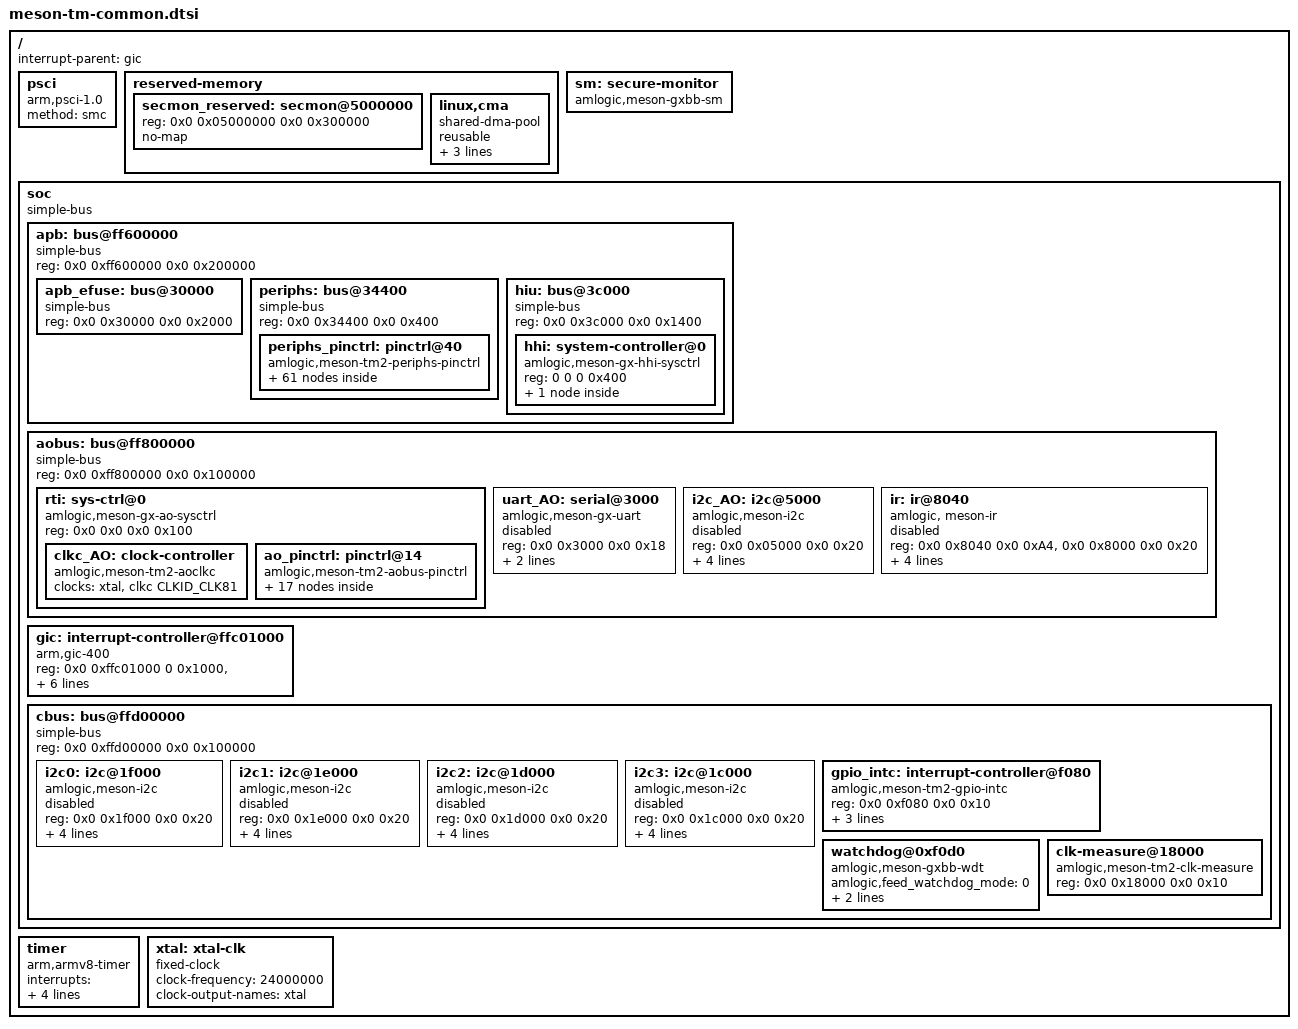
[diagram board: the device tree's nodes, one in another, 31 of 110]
// SPDX-License-Identifier: (GPL-2.0+ OR MIT)
/*
 * Copyright (c) 2018 Amlogic, Inc. All rights reserved.
 */

#include <dt-bindings/clock/tm2-clkc.h>
#include <dt-bindings/clock/tm2-aoclkc.h>
#include <dt-bindings/interrupt-controller/irq.h>
#include <dt-bindings/interrupt-controller/arm-gic.h>
#include <dt-bindings/gpio/gpio.h>
#include <dt-bindings/gpio/meson-tm2-gpio.h>
#include <dt-bindings/input/input.h>
#include <dt-bindings/input/meson_ir.h>
#include "meson-ir-map.dtsi"

/ {
	interrupt-parent = <&gic>;
	#address-cells = <2>;
	#size-cells = <2>;

	psci {
		compatible = "arm,psci-1.0";
		method = "smc";
	};

	reserved-memory {
		#address-cells = <2>;
		#size-cells = <2>;
		ranges;

		/* 3 MiB reserved for ARM Trusted Firmware (BL31) */
		secmon_reserved: secmon@5000000 {
			reg = <0x0 0x05000000 0x0 0x300000>;
			no-map;
		};
		linux,cma {
			compatible = "shared-dma-pool";
			reusable;
			size = <0x0 0x10000000>;
			alignment = <0x0 0x400000>;
			linux,cma-default;
		};
	};

	sm: secure-monitor {
		compatible = "amlogic,meson-gxbb-sm";
	};

	soc {
		compatible = "simple-bus";
		#address-cells = <2>;
		#size-cells = <2>;
		ranges;

		apb: bus@ff600000 {
			compatible = "simple-bus";
			reg = <0x0 0xff600000 0x0 0x200000>;
			#address-cells = <2>;
			#size-cells = <2>;
			ranges = <0x0 0x0 0x0 0xff600000 0x0 0x200000>;

			apb_efuse: bus@30000 {
				compatible = "simple-bus";
				reg = <0x0 0x30000 0x0 0x2000>;
				#address-cells = <2>;
				#size-cells = <2>;
				ranges = <0x0 0x0 0x0 0x30000 0x0 0x2000>;
			};

			periphs: bus@34400 {
				compatible = "simple-bus";
				reg = <0x0 0x34400 0x0 0x400>;
				#address-cells = <2>;
				#size-cells = <2>;
				ranges = <0x0 0x0 0x0 0x34400 0x0 0x400>;

				periphs_pinctrl: pinctrl@40 {
					compatible =
					"amlogic,meson-tm2-periphs-pinctrl";
					#address-cells = <2>;
					#size-cells = <2>;
					ranges;

					gpio: bank@40 {
						reg = <0x0 0x40  0x0 0x4c>,
						      <0x0 0xe8  0x0 0x18>,
						      <0x0 0x120 0x0 0x18>,
						      <0x0 0x2c0 0x0 0x40>,
						      <0x0 0x340 0x0 0x1c>;
						reg-names = "gpio",
							    "pull",
							    "pull-enable",
							    "mux",
							    "ds";
						gpio-controller;
						#gpio-cells = <2>;
						gpio-ranges = <&periphs_pinctrl
							      0 0 89>;
					};

					i2c0_c_pins:i2c0_c {
						mux {
							groups = "i2c0_sda_c",
								"i2c0_sck_c";
							function = "i2c0";
							bias-disable;
							drive-strength-microamp = <3000>;
						};
					};

					i2c0_c_pins_slp_input:i2c0_c_slp_input {
						mux {
							groups = "GPIOC_8", "GPIOC_9";
							function = "gpio_periphs";
							input-enable;
							bias-disable;
						};
					};

					i2c0_c_pins_slp_low:i2c0_c_slp_low {
						mux {
							groups = "GPIOC_8", "GPIOC_9";
							function = "gpio_periphs";
							output-low;
						};
					};

					i2c0_dv_pins:i2c0_dv {
						mux {
							groups = "i2c0_sda_dv",
								"i2c0_sck_dv";
							function = "i2c0";
							bias-disable;
							drive-strength-microamp = <3000>;
						};
					};

					i2c0_dv_pins_slp_input:i2c0_dv_slp_input {
						mux {
							groups = "GPIODV_0", "GPIODV_1";
							function = "gpio_periphs";
							input-enable;
							bias-disable;
						};
					};

					i2c0_dv_pins_slp_low:i2c0_dv_slp_low {
						mux {
							groups = "GPIODV_0", "GPIODV_1";
							function = "gpio_periphs";
							output-low;
						};
					};

					i2c1_z_pins:i2c1_z {
						mux {
							groups = "i2c1_sda_z",
								"i2c1_sck_z";
							function = "i2c1";
							bias-disable;
							drive-strength-microamp = <3000>;
						};
					};

					/*
					 * i2c sleep mode1: set the gpio the input
					 * in this scene, pull up power is off
					 */
					i2c1_z_pins_slp_input:i2c1_z_slp_input {
						mux {
							groups = "GPIOZ_1", "GPIOZ_2";
							function = "gpio_periphs";
							input-enable;
							bias-disable;
						};
					};

					/*
					 * i2c sleep mode2: set the gpio low
					 * in this scene, pull up power is on
					 */
					i2c1_z_pins_slp_low:i2c1_z_slp_low {
						mux {
							groups = "GPIOZ_1", "GPIOZ_2";
							function = "gpio_periphs";
							output-low;
						};
					};

					i2c1_h_pins:i2c1_h {
						mux {
							groups = "i2c1_sda_h",
								"i2c1_sck_h";
							function = "i2c1";
							bias-disable;
							drive-strength-microamp = <3000>;
						};
					};

					i2c1_h_pins_slp_input:i2c1_h_slp_input {
						mux {
							groups = "GPIOH_21", "GPIOH_22";
							function = "gpio_periphs";
							input-enable;
							bias-disable;
						};
					};

					i2c1_h_pins_slp_low:i2c1_h_slp_low {
						mux {
							groups = "GPIOH_21", "GPIOH_22";
							function = "gpio_periphs";
							output-low;
						};
					};

					i2c2_h_pins:i2c2_h {
						mux {
							groups = "i2c2_sda_h",
								"i2c2_sck_h";
							function = "i2c2";
							bias-disable;
							drive-strength-microamp = <3000>;
						};
					};

					i2c2_h_pins_slp_input:i2c2_h_slp_input {
						mux {
							groups = "GPIOH_19", "GPIOH_20";
							function = "gpio_periphs";
							input-enable;
							bias-disable;
						};
					};

					i2c2_h_pins_slp_low:i2c2_h_slp_low {
						mux {
							groups = "GPIOH_19", "GPIOH_20";
							function = "gpio_periphs";
							output-low;
						};
					};

					i2c2_z_pins:i2c2_z {
						mux {
							groups = "i2c2_sda_z",
								"i2c2_sck_z";
							function = "i2c2";
							bias-disable;
							drive-strength-microamp = <3000>;
						};
					};

					i2c2_z_pins_slp_input:i2c2_z_slp_input {
						mux {
							groups = "GPIOZ_9", "GPIOZ_10";
							function = "gpio_periphs";
							input-enable;
							bias-disable;
						};
					};

					i2c2_z_pins_slp_low:i2c2_z_slp_low {
						mux {
							groups = "GPIOZ_9", "GPIOZ_10";
							function = "gpio_periphs";
							output-low;
						};
					};

					i2c3_h1_pins:i2c3_h1 {
						mux {
							groups = "i2c3_sda_h1",
								"i2c3_sck_h0";
							function = "i2c3";
							bias-disable;
							drive-strength-microamp = <3000>;
						};
					};

					i2c3_h1_pins_slp_input:i2c3_h1_slp_input {
						mux {
							groups = "GPIOH_0", "GPIOH_1";
							function = "gpio_periphs";
							input-enable;
							bias-disable;
						};
					};

					i2c3_h1_pins_slp_low:i2c3_h1_slp_low {
						mux {
							groups = "GPIOH_0", "GPIOH_1";
							function = "gpio_periphs";
							output-low;
						};
					};

					i2c3_h20_pins:i2c3_h3 {
						mux {
							groups = "i2c3_sda_h20",
								"i2c3_sck_h19";
							function = "i2c3";
							bias-disable;
							drive-strength-microamp = <3000>;
						};
					};

					i2c3_h20_pins_slp_input:i2c3_h20_slp_input {
						mux {
							groups = "GPIOH_19", "GPIOH_20";
							function = "gpio_periphs";
							input-enable;
							bias-disable;
						};
					};

					i2c3_h20_pins_slp_low:i2c3_h20_slp_low {
						mux {
							groups = "GPIOH_19", "GPIOH_20";
							function = "gpio_periphs";
							output-low;
						};
					};

					i2c3_dv_pins:i2c3_dv {
						mux {
							groups = "i2c3_sda_dv",
								"i2c3_sck_dv";
							function = "i2c3";
							bias-disable;
							drive-strength-microamp = <3000>;
						};
					};

					i2c3_dv_pins_slp_input:i2c3_dv_slp_input {
						mux {
							groups = "GPIODV_9", "GPIODV_10";
							function = "gpio_periphs";
							input-enable;
							bias-disable;
						};
					};

					i2c3_dv_pins_slp_low:i2c3_dv_slp_low {
						mux {
							groups = "GPIODV_9", "GPIODV_10";
							function = "gpio_periphs";
							output-low;
						};
					};

					i2c3_c_pins:i2c3_c {
						mux {
							groups = "i2c3_sda_c",
								"i2c3_sck_c";
							function = "i2c3";
							bias-disable;
							drive-strength-microamp = <3000>;
						};
					};

					i2c3_c_pins_slp_input:i2c3_c_slp_input {
						mux {
							groups = "GPIOC_13", "GPIOC_14";
							function = "gpio_periphs";
							input-enable;
							bias-disable;
						};
					};

					i2c3_c_pins_slp_low:i2c3_c_slp_low {
						mux {
							groups = "GPIOC_13", "GPIOC_14";
							function = "gpio_periphs";
							output-low;
						};
					};
				};
			};

			hiu: bus@3c000 {
				compatible = "simple-bus";
				reg = <0x0 0x3c000 0x0 0x1400>;
				#address-cells = <2>;
				#size-cells = <2>;
				ranges = <0x0 0x0 0x0 0x3c000 0x0 0x1400>;

				hhi: system-controller@0 {
					compatible = "amlogic,meson-gx-hhi-sysctrl",
						     "simple-mfd", "syscon";
					reg = <0 0 0 0x400>;

					clkc: clock-controller {
						compatible = "amlogic,tm2-clkc";
						#clock-cells = <1>;
						clocks = <&xtal>;
						clock-names = "xtal";
					};
				};
			};
		};

		aobus: bus@ff800000 {
			compatible = "simple-bus";
			reg = <0x0 0xff800000 0x0 0x100000>;
			#address-cells = <2>;
			#size-cells = <2>;
			ranges = <0x0 0x0 0x0 0xff800000 0x0 0x100000>;

		rti: sys-ctrl@0 {
			compatible = "amlogic,meson-gx-ao-sysctrl",
					"simple-mfd", "syscon";
			reg = <0x0 0x0 0x0 0x100>;
			#address-cells = <2>;
			#size-cells = <2>;
			ranges = <0x0 0x0 0x0 0x0 0x0 0x100>;

			clkc_AO: clock-controller {
				compatible = "amlogic,meson-tm2-aoclkc";
				#clock-cells = <1>;
				clocks = <&xtal>, <&clkc CLKID_CLK81>;
				clock-names = "xtal", "mpeg-clk";
			};

			ao_pinctrl: pinctrl@14 {
				compatible = "amlogic,meson-tm2-aobus-pinctrl";
				#address-cells = <2>;
				#size-cells = <2>;
				ranges;

				gpio_ao: bank@14 {
					reg = <0x0 0x14 0x0 0x8>,
					      <0x0 0x1c 0x0 0x8>,
					      <0x0 0x24 0x0 0x14>;
					reg-names = "mux",
						    "ds",
						    "gpio";
					gpio-controller;
					#gpio-cells = <2>;
					gpio-ranges = <&ao_pinctrl 0 0 15>;
				};

				i2c_ao_2_pins:i2c_ao_2 {
					mux {
						groups = "i2c_ao_sck_2",
						"i2c_ao_sda_3";
						function = "i2c_ao";
						bias-disable;
						drive-strength-microamp = <3000>;
					};
				};

				i2c_ao_2_pins_slp_input:i2c_ao_2_slp_input {
					mux {
						groups = "GPIOAO_2", "GPIOAO_3";
						function = "gpio_aobus";
						input-enable;
						bias-disable;
					};
				};

				i2c_ao_2_pins_slp_low:i2c_ao_2_slp_low {
					mux {
						groups = "GPIOAO_2", "GPIOAO_3";
						function = "gpio_aobus";
						output-low;
					};
				};

				i2c_ao_e_pins:i2c_ao_e {
					mux {
						groups = "i2c_ao_sck_e",
						"i2c_ao_sda_e";
						function = "i2c_ao";
						bias-disable;
						drive-strength-microamp = <3000>;
					};
				};

				i2c_ao_e_pins_slp_input:i2c_ao_e_slp_input {
					mux {
						groups = "GPIOE_0", "GPIOE_1";
						function = "gpio_aobus";
						input-enable;
						bias-disable;
					};
				};

				i2c_ao_e_pins_slp_low:i2c_ao_e_slp_low {
					mux {
						groups = "GPIOE_0", "GPIOE_1";
						function = "gpio_aobus";
						output-low;
					};
				};

				i2c_ao_slave_pins:i2c_ao_slave {
					mux {
						groups = "i2c_ao_slave_sck",
						"i2c_ao_slave_sda";
						function = "i2c_ao_slave";
					};
				};

				remote_input_ao_pins: remote-input-ao {
					mux {
						groups = "remote_input_ao";
						function = "remote_input_ao";
						bias-disable;
					};
				};
			};
		};

			uart_AO: serial@3000 {
				compatible = "amlogic,meson-gx-uart",
					     "amlogic,meson-ao-uart";
				reg = <0x0 0x3000 0x0 0x18>;
				interrupts = <GIC_SPI 193 IRQ_TYPE_EDGE_RISING>;
				clocks = <&xtal>, <&xtal>, <&xtal>;
				clock-names = "xtal", "pclk", "baud";
				status = "disabled";
			};

			i2c_AO: i2c@5000 {
				compatible = "amlogic,meson-i2c";
				status = "disabled";
				reg = <0x0 0x05000 0x0 0x20>;
				interrupts = <GIC_SPI 195 IRQ_TYPE_EDGE_RISING>,
					<GIC_SPI 201 IRQ_TYPE_EDGE_RISING>;
				#address-cells = <2>;
				#size-cells = <2>;
				clocks = <&clkc CLKID_I2C>;
				clock-frequency = <100000>;
			};

			ir: ir@8040 {
				compatible = "amlogic, meson-ir";
				reg = <0x0 0x8040 0x0 0xA4>,
				      <0x0 0x8000 0x0 0x20>;
				status = "disabled";
				protocol = <REMOTE_TYPE_NEC>;
				interrupts = <GIC_SPI 196 IRQ_TYPE_EDGE_RISING>;
				map = <&custom_maps>;
				max_frame_time = <200>;
			};
		};

		gic: interrupt-controller@ffc01000 {
			compatible = "arm,gic-400";
			reg = <0x0 0xffc01000 0 0x1000>,
			      <0x0 0xffc02000 0 0x2000>,
			      <0x0 0xffc04000 0 0x2000>,
			      <0x0 0xffc06000 0 0x2000>;
			interrupt-controller;
			interrupts = <GIC_PPI 9
				(GIC_CPU_MASK_SIMPLE(8) | IRQ_TYPE_LEVEL_HIGH)>;
			#interrupt-cells = <3>;
			#address-cells = <0>;
		};

		cbus: bus@ffd00000 {
			compatible = "simple-bus";
			reg = <0x0 0xffd00000 0x0 0x100000>;
			#address-cells = <2>;
			#size-cells = <2>;
			ranges = <0x0 0x0 0x0 0xffd00000 0x0 0x100000>;

			i2c0: i2c@1f000 {
				compatible = "amlogic,meson-i2c";
				status = "disabled";
				reg = <0x0 0x1f000 0x0 0x20>;
				interrupts = <GIC_SPI 21 IRQ_TYPE_EDGE_RISING>,
					<GIC_SPI 91 IRQ_TYPE_EDGE_RISING>;
				#address-cells = <1>;
				#size-cells = <0>;
				clocks = <&clkc CLKID_I2C>;
				clock-frequency = <100000>;
			};

			i2c1: i2c@1e000 {
				compatible = "amlogic,meson-i2c";
				status = "disabled";
				reg = <0x0 0x1e000 0x0 0x20>;
				interrupts = <GIC_SPI 214 IRQ_TYPE_EDGE_RISING>,
					<GIC_SPI 92 IRQ_TYPE_EDGE_RISING>;
				#address-cells = <1>;
				#size-cells = <0>;
				clocks = <&clkc CLKID_I2C>;
				clock-frequency = <100000>;
			};

			i2c2: i2c@1d000 {
				compatible = "amlogic,meson-i2c";
				status = "disabled";
				reg = <0x0 0x1d000 0x0 0x20>;
				interrupts = <GIC_SPI 215 IRQ_TYPE_EDGE_RISING>,
					<GIC_SPI 94 IRQ_TYPE_EDGE_RISING>;
				#address-cells = <1>;
				#size-cells = <0>;
				clocks = <&clkc CLKID_I2C>;
				clock-frequency = <100000>;
			};

			i2c3: i2c@1c000 {
				compatible = "amlogic,meson-i2c";
				status = "disabled";
				reg = <0x0 0x1c000 0x0 0x20>;
				interrupts = <GIC_SPI 39 IRQ_TYPE_EDGE_RISING>,
					<GIC_SPI 95 IRQ_TYPE_EDGE_RISING>;
				#address-cells = <1>;
				#size-cells = <0>;
				clocks = <&clkc CLKID_I2C>;
				clock-frequency = <100000>;
			};

			gpio_intc: interrupt-controller@f080 {
				compatible = "amlogic,meson-tm2-gpio-intc",
					     "amlogic,meson-gpio-intc";
				reg = <0x0 0xf080 0x0 0x10>;
				interrupt-controller;
				#interrupt-cells = <2>;
				amlogic,channel-interrupts =
						<64 65 66 67 68 69 70 71>;
			};

			watchdog@0xf0d0 {
				compatible = "amlogic,meson-gxbb-wdt";
				status = "okay";
				/* 0:userspace, 1:kernel */
				amlogic,feed_watchdog_mode = <0>;
				reg = <0x0 0xf0d0 0x0 0x10>;
				clocks = <&xtal>;
			};

			clk-measure@18000 {
				compatible = "amlogic,meson-tm2-clk-measure";
				reg = <0x0 0x18000 0x0 0x10>;
			};
		};

	};

	timer {
		compatible = "arm,armv8-timer";
		interrupts = <GIC_PPI 13
			(GIC_CPU_MASK_RAW(0xff) | IRQ_TYPE_LEVEL_LOW)>,
			     <GIC_PPI 14
			(GIC_CPU_MASK_RAW(0xff) | IRQ_TYPE_LEVEL_LOW)>,
			     <GIC_PPI 11
			(GIC_CPU_MASK_RAW(0xff) | IRQ_TYPE_LEVEL_LOW)>,
			     <GIC_PPI 10
			(GIC_CPU_MASK_RAW(0xff) | IRQ_TYPE_LEVEL_LOW)>;
	};

	xtal: xtal-clk {
		compatible = "fixed-clock";
		clock-frequency = <24000000>;
		clock-output-names = "xtal";
		#clock-cells = <0>;
	};
};
